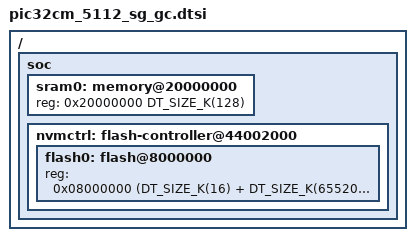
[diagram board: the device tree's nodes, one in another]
/*
 * Copyright (c) 2026 Microchip Technology Inc.
 *
 * SPDX-License-Identifier: Apache-2.0
 */

/ {
	soc {
		sram0: memory@20000000 {
			reg = <0x20000000 DT_SIZE_K(128)>;
			ranges = <0x0 0x20000000 DT_SIZE_K(128)>;
		};

		nvmctrl: flash-controller@44002000 {
			flash0: flash@8000000 {
				/*
				 * Unified flash address space:
				 *   BFM: 16 KB   @ 0x08000000 - 0x08003FFF
				 *   Gap: 64496KB @ 0x08004000 - 0x0BFFFFFF (unimplemented)
				 *   PFM: 512 KB  @ 0x0C000000 - 0x0C07FFFF
				 *
				 * Total addressable: BFM + gap + PFM
				 */
				reg = <0x08000000
				       (DT_SIZE_K(16) + DT_SIZE_K(65520) + DT_SIZE_K(512))>;
				#address-cells = <1>;
				#size-cells = <1>;
				ranges = <0x0 0x08000000
					  (DT_SIZE_K(16) + DT_SIZE_K(65520) + DT_SIZE_K(512))>;
			};
		};
	};
};
